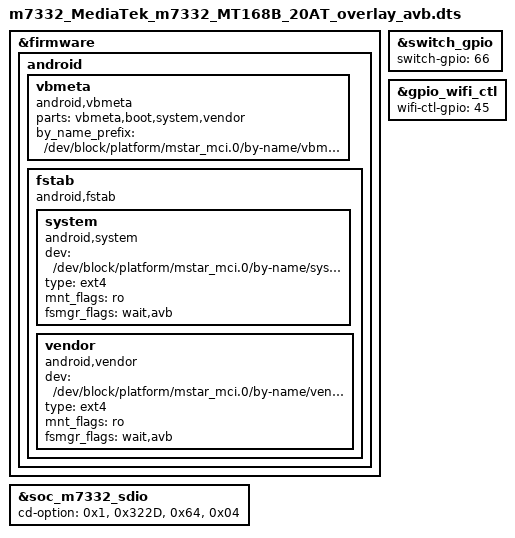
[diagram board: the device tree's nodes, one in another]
/dts-v1/;
/plugin/;

&firmware {
	android {
		vbmeta {
			compatible = "android,vbmeta";
			parts = "vbmeta,boot,system,vendor";
			by_name_prefix ="/dev/block/platform/mstar_mci.0/by-name/vbmeta";
		};
		fstab {
			compatible = "android,fstab";
			system {
				compatible = "android,system";
				dev = "/dev/block/platform/mstar_mci.0/by-name/system";
				type = "ext4";
				mnt_flags = "ro";
				fsmgr_flags = "wait,avb";
			};
			vendor {
				compatible = "android,vendor";
				dev = "/dev/block/platform/mstar_mci.0/by-name/vendor";
				type = "ext4";
				mnt_flags = "ro";
				fsmgr_flags = "wait,avb";
			};
		};
	};
};

&switch_gpio {
	switch-gpio = <66>;
};

&gpio_wifi_ctl {
	wifi-ctl-gpio = <45>;
};

&soc_m7332_sdio {
	cd-option = <0x1>, <0x322D>, <0x64>, <0x04>;
};
